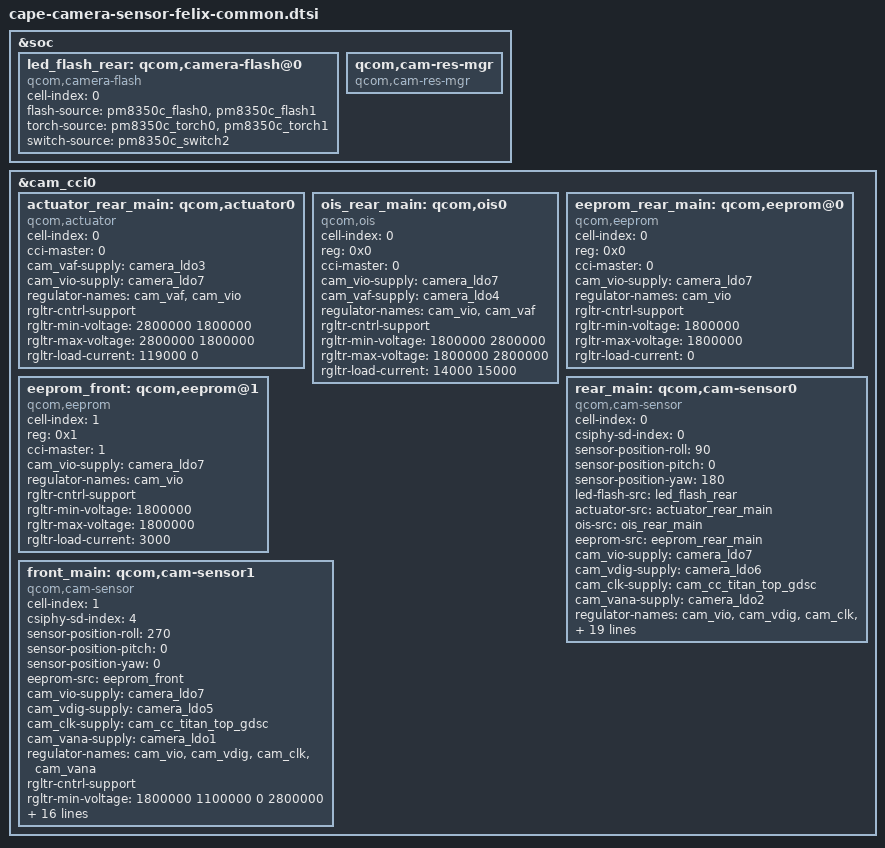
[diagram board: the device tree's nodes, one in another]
/*
   This base is original from "waipio-camera-sensor-mtp.dtsi"
*/
#include <dt-bindings/clock/qcom,camcc-waipio.h>

&soc {
/*
   The led config may not be correct. TBD
*/
	led_flash_rear: qcom,camera-flash@0 {
		cell-index = <0>;
		compatible = "qcom,camera-flash";
		flash-source = <&pm8350c_flash0 &pm8350c_flash1>;
		torch-source = <&pm8350c_torch0 &pm8350c_torch1>;
		switch-source = <&pm8350c_switch2>;
		status = "ok";
	};

	qcom,cam-res-mgr {
		compatible = "qcom,cam-res-mgr";
		status = "ok";
	};
};

&cam_cci0 {
	actuator_rear_main: qcom,actuator0 {
		cell-index = <0>;
		compatible = "qcom,actuator";
		cci-master = <0>;
		cam_vaf-supply = <&camera_ldo3>;
		cam_vio-supply = <&camera_ldo7>;
		regulator-names = "cam_vaf", "cam_vio";
		rgltr-cntrl-support;
		rgltr-min-voltage = <2800000 1800000>;
		rgltr-max-voltage = <2800000 1800000>;
		rgltr-load-current = <119000 0>;
	};

	ois_rear_main: qcom,ois0 {
		cell-index = <0>;
		reg = <0x0>;
		compatible = "qcom,ois";
		cci-master = <0>;
		cam_vio-supply = <&camera_ldo7>;
		cam_vaf-supply = <&camera_ldo4>;
		regulator-names = "cam_vio", "cam_vaf";
		rgltr-cntrl-support;
		rgltr-min-voltage = <1800000 2800000>;
		rgltr-max-voltage = <1800000 2800000>;
		rgltr-load-current = <14000 15000>;
		status = "ok";
	};

	eeprom_rear_main: qcom,eeprom@0 {
		cell-index = <0>;
		reg = <0x0>;
		compatible = "qcom,eeprom";
		cci-master = <0>;
		cam_vio-supply = <&camera_ldo7>;
		regulator-names = "cam_vio";
		rgltr-cntrl-support;
		rgltr-min-voltage = <1800000>;
		rgltr-max-voltage = <1800000>;
		rgltr-load-current = <0>;
	};

	rear_main: qcom,cam-sensor0 {
		cell-index = <0>;
		compatible = "qcom,cam-sensor";
		csiphy-sd-index = <0>;
		sensor-position-roll = <90>;
		sensor-position-pitch = <0>;
		sensor-position-yaw = <180>;
		led-flash-src = <&led_flash_rear>;
		actuator-src = <&actuator_rear_main>;
		ois-src = <&ois_rear_main>;
		eeprom-src = <&eeprom_rear_main>;
		cam_vio-supply = <&camera_ldo7>;
		cam_vdig-supply = <&camera_ldo6>;
		cam_clk-supply = <&cam_cc_titan_top_gdsc>;
		cam_vana-supply = <&camera_ldo2>;
		regulator-names = "cam_vio", "cam_vdig",
			"cam_clk", "cam_vana";
		rgltr-cntrl-support;
		rgltr-min-voltage = <1800000 1100000 0 2800000>;
		rgltr-max-voltage = <1800000 1100000 0 2800000>;
		rgltr-load-current = <3000 675000 0 112000>;
		gpio-no-mux = <0>;
		pinctrl-names = "cam_default", "cam_suspend";
		pinctrl-0 = <&cam_sensor_mclk0_active
			&cam_sensor_active_rst0>;
		pinctrl-1 = <&cam_sensor_mclk0_suspend
			&cam_sensor_suspend_rst0>;
		gpios = <&tlmm 100 0>,
			<&tlmm 25 0>;
		gpio-reset = <1>;
		gpio-req-tbl-num = <0 1>;
		gpio-req-tbl-flags = <1 0>;
		gpio-req-tbl-label = "CAMIF_MCLK0",
					"CAM_RESET0";
		cci-master = <0>;
		clocks = <&clock_camcc CAM_CC_MCLK0_CLK>;
		clock-names = "cam_clk";
		clock-cntl-level = "nominal";
		clock-rates = <24000000>;
		status = "ok";
	};

	eeprom_front: qcom,eeprom@1 {
		cell-index = <1>;
		reg = <0x1>;
		compatible = "qcom,eeprom";
		cci-master = <1>;
		cam_vio-supply = <&camera_ldo7>;
		regulator-names = "cam_vio";
		rgltr-cntrl-support;
		rgltr-min-voltage = <1800000>;
		rgltr-max-voltage = <1800000>;
		rgltr-load-current = <3000>;
	};

	front_main: qcom,cam-sensor1 {
		cell-index = <1>;
		compatible = "qcom,cam-sensor";
		csiphy-sd-index = <4>;
		sensor-position-roll = <270>;
		sensor-position-pitch = <0>;
		sensor-position-yaw = <0>;
		eeprom-src = <&eeprom_front>;
		cam_vio-supply = <&camera_ldo7>;
		cam_vdig-supply = <&camera_ldo5>;
		cam_clk-supply = <&cam_cc_titan_top_gdsc>;
		cam_vana-supply = <&camera_ldo1>;
		regulator-names = "cam_vio", "cam_vdig",
			"cam_clk", "cam_vana";
		rgltr-cntrl-support;
		rgltr-min-voltage = <1800000 1100000 0 2800000>;
		rgltr-max-voltage = <1800000 1100000 0 2800000>;
		rgltr-load-current = <3000 283000 0 50000>;
		gpio-no-mux = <0>;
		pinctrl-names = "cam_default", "cam_suspend";
		pinctrl-0 = <&cam_sensor_mclk4_active
			&cam_sensor_active_rst4>;
		pinctrl-1 = <&cam_sensor_mclk4_suspend
			&cam_sensor_suspend_rst4>;
		gpios = <&tlmm 104 0>,
			<&tlmm 108 0>;
		gpio-reset = <1>;
		gpio-req-tbl-num = <0 1>;
		gpio-req-tbl-flags = <1 0>;
		gpio-req-tbl-label = "CAMIF_MCLK4",
					"CAM_RESET4";
		cci-master = <1>;
		clocks = <&clock_camcc CAM_CC_MCLK4_CLK>;
		clock-names = "cam_clk";
		clock-cntl-level = "nominal";
		clock-rates = <19200000>;
		status = "ok";
	};
};

